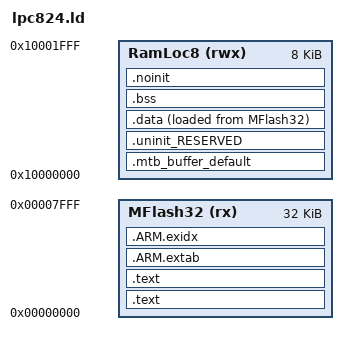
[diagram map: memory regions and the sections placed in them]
/*
 * GENERATED FILE - DO NOT EDIT
 * (c) Code Red Technologies Ltd, 2008-2013
 * (c) NXP Semiconductors 2013-2016
 * Generated linker script file for LPC824
 * Created from linkscript.ldt by FMCreateLinkLibraries
 * Using Freemarker v2.3.23
 * LPCXpresso v8.2.2 [Build 650] [2016-09-09]  on Nov 2, 2016 11:00:41 PM
 */

/*
GROUP (
  libcr_c.a
  libcr_eabihelpers.a
)*/

MEMORY
{
  /* Define each memory region */
  MFlash32 (rx) : ORIGIN = 0x0, LENGTH = 0x8000 /* 32K bytes (alias Flash) */  
  RamLoc8 (rwx) : ORIGIN = 0x10000000, LENGTH = 0x2000 /* 8K bytes (alias RAM) */  
}

  /* Define a symbol for the top of each memory region */
  __base_MFlash32 = 0x0  ; /* MFlash32 */  
  __base_Flash = 0x0 ; /* Flash */  
  __top_MFlash32 = 0x0 + 0x8000 ; /* 32K bytes */  
  __top_Flash = 0x0 + 0x8000 ; /* 32K bytes */  
  __base_RamLoc8 = 0x10000000  ; /* RamLoc8 */  
  __base_RAM = 0x10000000 ; /* RAM */  
  __top_RamLoc8 = 0x10000000 + 0x2000 ; /* 8K bytes */  
  __top_RAM = 0x10000000 + 0x2000 ; /* 8K bytes */  

ENTRY(ResetISR)

SECTIONS
{
    /* MAIN TEXT SECTION */
    .text : ALIGN(4)
    {
        FILL(0xff)
        __vectors_start__ = ABSOLUTE(.) ;
        KEEP(*(.isr_vector))
        /* Global Section Table */
        . = ALIGN(4) ; 
        __section_table_start = .;
        __data_section_table = .;
        LONG(LOADADDR(.data));
        LONG(    ADDR(.data));
        LONG(  SIZEOF(.data));
        __data_section_table_end = .;
        __bss_section_table = .;
        LONG(    ADDR(.bss));
        LONG(  SIZEOF(.bss));
        __bss_section_table_end = .;
        __section_table_end = . ;
	    /* End of Global Section Table */

        *(.after_vectors*)

    } >MFlash32

    .text : ALIGN(4)    
    {
        *(.text*)
        *(.rodata .rodata.* .constdata .constdata.*)
        . = ALIGN(4);
    } > MFlash32
    /*
     * for exception handling/unwind - some Newlib functions (in common
     * with C++ and STDC++) use this. 
     */
    .ARM.extab : ALIGN(4) 
    {
        *(.ARM.extab* .gnu.linkonce.armextab.*)
    } > MFlash32
    __exidx_start = .;

    .ARM.exidx : ALIGN(4)
    {
        *(.ARM.exidx* .gnu.linkonce.armexidx.*)
    } > MFlash32
    __exidx_end = .;

    _etext = .;
        
    /* MAIN DATA SECTION */
        /* Default MTB section */
        .mtb_buffer_default (NOLOAD) :
        {
           KEEP(*(.mtb*))
        } > RamLoc8
    .uninit_RESERVED : ALIGN(4)
    {
        KEEP(*(.bss.$RESERVED*))
        . = ALIGN(4) ;
        _end_uninit_RESERVED = .;
    } > RamLoc8
    /* Main DATA section (RamLoc8) */
    .data : ALIGN(4)
    {
       FILL(0xff)
       _data = . ;
       *(vtable)
       *(.ramfunc*)
       *(.data*)
       . = ALIGN(4) ;
       _edata = . ;
    } > RamLoc8 AT>MFlash32
    /* MAIN BSS SECTION */
    .bss : ALIGN(4)
    {
        _bss = .;
        *(.bss*)
        *(COMMON)
        . = ALIGN(4) ;
        _ebss = .;
        PROVIDE(end = .);
    } > RamLoc8
    /* DEFAULT NOINIT SECTION */
    .noinit (NOLOAD): ALIGN(4)
    {
        _noinit = .;
        *(.noinit*) 
         . = ALIGN(4) ;
        _end_noinit = .;
    } > RamLoc8

    PROVIDE(_pvHeapStart = DEFINED(__user_heap_base) ? __user_heap_base : .);
    PROVIDE(_vStackTop = DEFINED(__user_stack_top) ? __user_stack_top : __top_RamLoc8 - 0);

    /* ## Create checksum value (used in startup) ## */
    PROVIDE(__valid_user_code_checksum = 0 - 
                                         (_vStackTop 
                                         + (ResetISR + 1) 
                                         + (( DEFINED(NMI_Handler) ? NMI_Handler : M0_NMI_Handler ) + 1) 
                                         + (( DEFINED(HardFault_Handler) ? HardFault_Handler : M0_HardFault_Handler ) + 1) 
                                         )
           );
}
